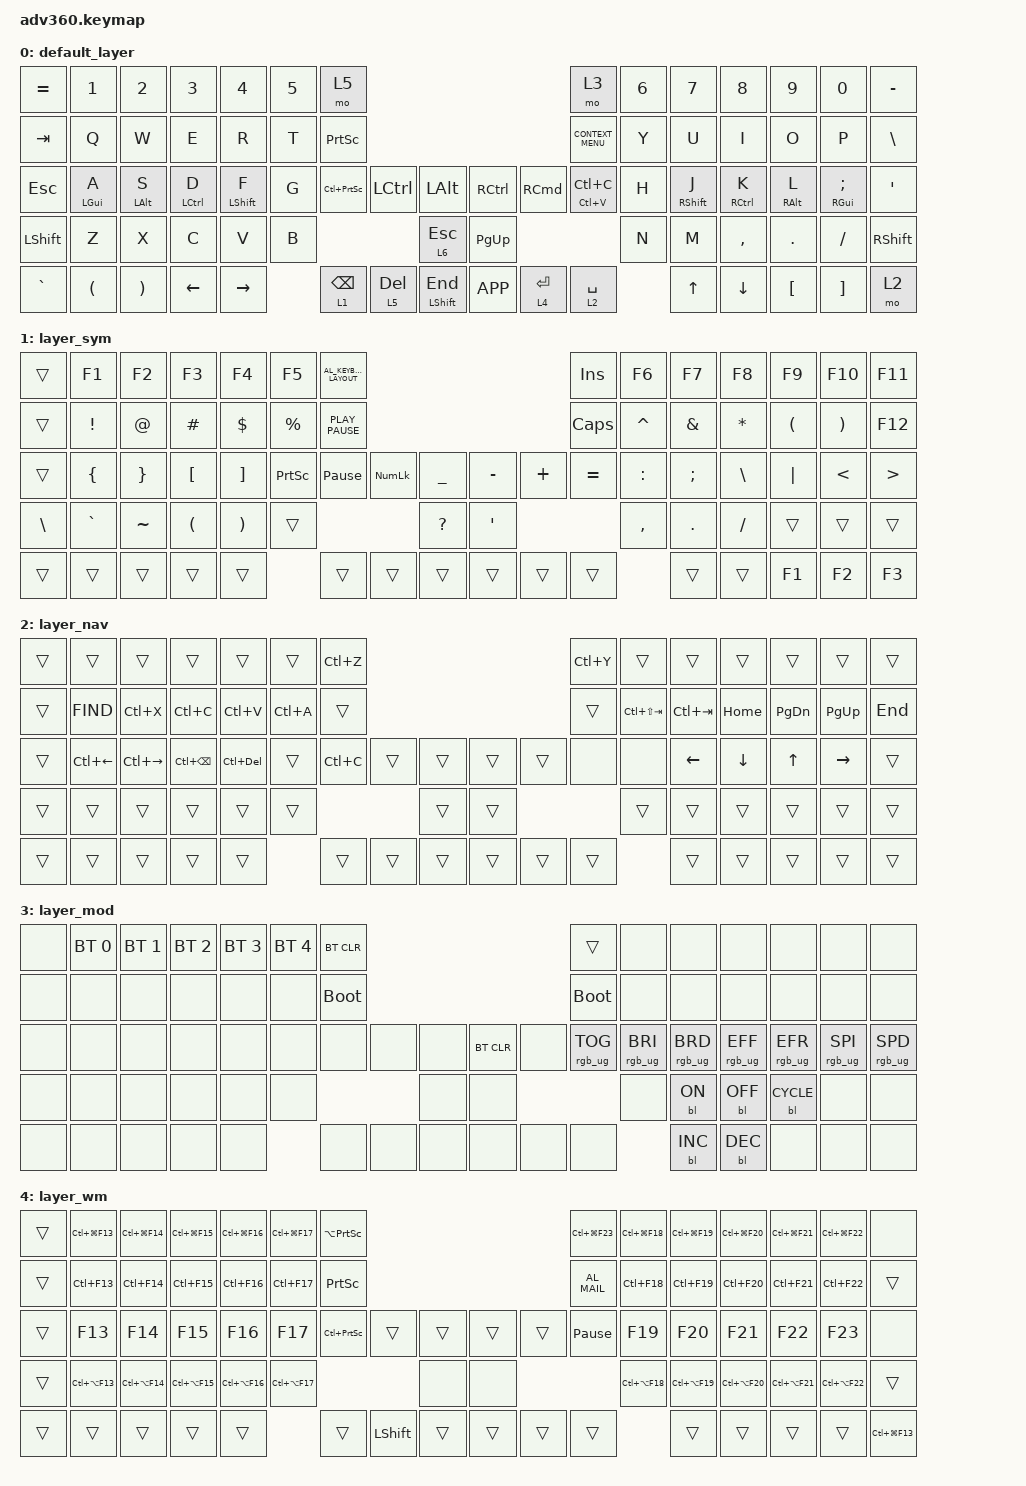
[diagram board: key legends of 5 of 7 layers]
/*
 * ZMK keymap for Kinesis Advantage360 Pro
 * Layers:
 * 0 BASE (QWERTY + HRM; thumb: tap End / hold Shift)
 * 1 SYM  (hold BSPC/DEL)
 * 2 NAV  (hold SPACE)
 * 3 MOD  (BT/RGB/boot)
 * 4 WM   (hold ENTER) -> focus with Enter+key; move requires Shift
 * 5 NUMPAD (momentary from base top row)
 * 6 APP  (hold CAPS position, tap ESC) -> Ctrl+Alt+Win+<key> for quicklaunch/system binds
 */

#include <behaviors.dtsi>
#include <dt-bindings/zmk/backlight.h>
#include <dt-bindings/zmk/bt.h>
#include <dt-bindings/zmk/keys.h>
#include <dt-bindings/zmk/rgb.h>

/ {
    behaviors {
        hm: home_row_mods {
            compatible = "zmk,behavior-hold-tap";
            label = "HOME_ROW_MODS";
            #binding-cells = <2>;
            tapping-term-ms = <200>;
            quick-tap-ms = <0>;
            require-prior-idle-ms = <150>;
            flavor = "tap-preferred";
            bindings = <&kp>, <&kp>;
        };
    };

    keymap {
        compatible = "zmk,keymap";

        // =========================================================
        // LAYER 0: BASE
        // =========================================================

        default_layer {
            bindings = <
&kp EQUAL  &kp N1                &kp N2                 &kp N3       &kp N4       &kp N5  &mo 5                                                                            &mo 3               &kp N6  &kp N7       &kp N8       &kp N9      &kp N0         &kp MINUS
&kp TAB    &kp Q                 &kp W                  &kp E        &kp R        &kp T   &kp PRINTSCREEN                                                                  &kp K_CONTEXT_MENU  &kp Y   &kp U        &kp I        &kp O       &kp P          &kp BSLH
&kp ESC    &hm LGUI A            &hm LALT S             &hm LCTRL D  &hm LSHFT F  &kp G   &kp LC(PRINTSCREEN)  &kp LCTRL  &kp LEFT_ALT       &kp RCTRL  &kp RIGHT_COMMAND  &mt LC(V) LC(C)     &kp H   &hm RSHFT J  &hm RCTRL K  &hm RALT L  &hm RGUI SEMI  &kp SQT
&kp LSHFT  &kp Z                 &kp X                  &kp C        &kp V        &kp B                                   &lt 6 ESC          &kp PG_UP                                         &kp N   &kp M        &kp COMMA    &kp DOT     &kp FSLH       &kp RSHFT
&kp GRAVE  &kp LEFT_PARENTHESIS  &kp RIGHT_PARENTHESIS  &kp LEFT     &kp RIGHT            &lt 1 BSPC           &lt 5 DEL  &mt LSHFT END      &kp K_APP  &lt 4 ENTER        &lt 2 SPACE                 &kp UP       &kp DOWN     &kp LBKT    &kp RBKT       &mo 2
            >;
        };

        // =========================================================
        // LAYER 1: SYM
        // =========================================================

        layer_sym {
            bindings = <
&trans    &kp F1     &kp F2     &kp F3                &kp F4                 &kp F5           &kp C_AL_KEYBOARD_LAYOUT                                                  &kp INS    &kp F6     &kp F7    &kp F8         &kp F9    &kp F10   &kp F11
&trans    &kp EXCL   &kp AT     &kp HASH              &kp DLLR               &kp PRCNT        &kp K_PLAY_PAUSE                                                          &kp CAPS   &kp CARET  &kp AMPS  &kp STAR       &kp LPAR  &kp RPAR  &kp F12
&trans    &kp LBRC   &kp RBRC   &kp LBKT              &kp RBKT               &kp PRINTSCREEN  &kp PAUSE_BREAK           &kp KP_NUM  &kp UNDER      &kp MINUS  &kp PLUS  &kp EQUAL  &kp COLON  &kp SEMI  &kp BACKSLASH  &kp PIPE  &kp LT    &kp GT
&kp BSLH  &kp GRAVE  &kp TILDE  &kp LEFT_PARENTHESIS  &kp RIGHT_PARENTHESIS  &trans                                                 &kp QMARK      &kp SQT                         &kp COMMA  &kp DOT   &kp FSLH       &trans    &trans    &trans
&trans    &trans     &trans     &trans                &trans                                  &trans                    &trans      &trans         &trans     &trans    &trans                &trans    &trans         &kp F1    &kp F2    &kp F3
            >;
        };

        // =========================================================
        // LAYER 2: NAV
        // =========================================================

        layer_nav {
            bindings = <
&trans  &trans        &trans         &trans        &trans       &trans  &kp LC(Z)                                      &kp LC(Y)  &trans       &trans    &trans          &trans        &trans     &trans
&trans  &kp K_FIND    &kp LC(X)      &kp LC(C)     &kp LC(V)    &kp LC(A)  &trans                                      &trans     &kp LC(LS(TAB))  &kp LC(TAB)  &kp HOME  &kp PAGE_DOWN  &kp PG_UP  &kp END
&trans  &kp LC(LEFT)  &kp LC(RIGHT)  &kp LC(BSPC)  &kp LC(DEL)  &trans  &kp LC(C)  &trans  &trans      &trans  &trans  &none      &none        &kp LEFT  &kp DOWN_ARROW  &kp UP_ARROW  &kp RIGHT  &trans
&trans  &trans        &trans         &trans        &trans       &trans                     &trans      &trans                     &trans       &trans    &trans          &trans        &trans     &trans
&trans  &trans        &trans         &trans        &trans               &trans     &trans  &trans      &trans  &trans  &trans                  &trans    &trans          &trans        &trans     &trans
            >;
        };

        // =========================================================
        // LAYER 3: MOD (BT/RGB/boot)
        // =========================================================

        layer_mod {
            bindings = <
&none  &bt BT_SEL 0  &bt BT_SEL 1  &bt BT_SEL 2  &bt BT_SEL 3  &bt BT_SEL 4  &bt BT_CLR                                        &trans           &none            &none            &none            &none            &none            &none
&none  &none         &none         &none         &none         &none         &bootloader                                       &bootloader      &none            &none            &none            &none            &none            &none
&none  &none         &none         &none         &none         &none         &none        &none  &none      &bt BT_CLR  &none  &rgb_ug RGB_TOG  &rgb_ug RGB_BRI  &rgb_ug RGB_BRD  &rgb_ug RGB_EFF  &rgb_ug RGB_EFR  &rgb_ug RGB_SPI  &rgb_ug RGB_SPD
&none  &none         &none         &none         &none         &none                             &none      &none                               &none            &bl BL_ON        &bl BL_OFF       &bl BL_CYCLE     &none            &none
&none  &none         &none         &none         &none                       &none        &none  &none      &none       &none  &none                             &bl BL_INC       &bl BL_DEC       &none            &none            &none
            >;
        };

        // =========================================================
        // LAYER 4: WM
        // =========================================================

        layer_wm {
            bindings = <
&trans  &kp LC(LG(F13))  &kp LC(LG(F14))  &kp LC(LG(F15))  &kp LC(LG(F16))  &kp LC(LG(F17))  &kp LA(PRINTSCREEN)                                              &kp LC(LG(F23))  &kp LC(LG(F18))  &kp LC(LG(F19))  &kp LC(LG(F20))  &kp LC(LG(F21))  &kp LC(LG(F22))  &none
&trans  &kp LC(F13)      &kp LC(F14)      &kp LC(F15)      &kp LC(F16)      &kp LC(F17)      &kp PRINTSCREEN                                                  &kp C_AL_MAIL    &kp LC(F18)      &kp LC(F19)      &kp LC(F20)      &kp LC(F21)      &kp LC(F22)      &trans
&trans  &kp F13          &kp F14          &kp F15          &kp F16          &kp F17          &kp LC(PSCRN)        &trans          &trans      &trans  &trans  &kp PAUSE_BREAK  &kp F19          &kp F20          &kp F21          &kp F22          &kp F23          &none
&trans  &kp LC(LA(F13))  &kp LC(LA(F14))  &kp LC(LA(F15))  &kp LC(LA(F16))  &kp LC(LA(F17))                                       &none       &none                            &kp LC(LA(F18))  &kp LC(LA(F19))  &kp LC(LA(F20))  &kp LC(LA(F21))  &kp LC(LA(F22))  &trans
&trans  &trans           &trans           &trans           &trans                            &trans               &kp LEFT_SHIFT  &trans      &trans  &trans  &trans                            &trans           &trans           &trans           &trans           &kp LC(LG(F13))
            >;
        };

        // =========================================================
        // LAYER 5: NUMPAD
        // =========================================================

        layer_numpad {
            bindings = <
&trans  &trans    &trans  &trans     &trans    &trans       &trans                                                                 &trans  &trans           &kp MINUS     &kp PLUS      &kp EQUAL     &kp PIPE       &trans
&trans  &trans    &trans  &trans     &trans    &trans       &kp KP_SLASH                                                           &trans  &trans           &kp N7        &kp N8        &kp N9        &kp BACKSLASH  &trans
&trans  &kp EXCL  &kp AT  &kp POUND  &kp DLLR  &kp PERCENT  &kp KP_MULTIPLY  &trans  &trans            &trans       &trans         &trans  &kp LOCKING_NUM  &kp NUMBER_4  &kp N5        &kp NUMBER_6  &kp DOT        &trans
&trans  &trans    &trans  &trans     &trans    &trans                                &kp KP_MINUS      &kp KP_PLUS                         &kp N0           &kp NUMBER_1  &kp NUMBER_2  &kp NUMBER_3  &kp SLASH      &trans
&trans  &trans    &trans  &trans     &trans                 &trans           &trans  &trans            &trans       &kp BACKSPACE  &trans                   &kp N0        &trans        &trans        &trans
            >;
        };

        // =========================================================
        // LAYER 6: APP (USE ALL KEYS)
        // Hold the CAPS-position key to access, tap it for ESC.
        // Sends Ctrl+Alt+Win+<key> for every position (except the held APP key).
        // Bind these in GlazeWM to launch apps / scripts.
        // =========================================================

        layer_app {
            bindings = <
&kp LC(LA(LG(EQUAL)))  &kp LC(LA(LG(N1)))     &kp LC(LA(LG(N2)))  &kp LC(LA(LG(N3)))    &kp LC(LA(LG(N4)))     &kp LC(LA(LG(N5)))  &kp LC(LA(LG(F1)))                                                                                                 &kp LC(LA(LG(F2)))     &kp LC(LA(LG(N6)))  &kp LC(LA(LG(N7)))  &kp LC(LA(LG(N8)))     &kp LC(LA(LG(N9)))    &kp LC(LA(LG(N0)))    &kp LC(LA(LG(MINUS)))
&kp LC(LA(LG(TAB)))    &kp LC(LA(LG(Q)))      &kp LC(LA(LG(W)))   &kp LC(LA(LG(E)))     &kp LC(LA(LG(R)))      &kp LC(LA(LG(T)))   &kp LC(LA(LG(F3)))                                                                                                 &kp LC(LA(LG(F4)))     &kp LC(LA(LG(Y)))   &kp LC(LA(LG(U)))   &kp LC(LA(LG(I)))      &kp LC(LA(LG(O)))     &kp LC(LA(LG(P)))     &kp LC(LA(LG(BSLH)))
&kp LC(LA(LG(ESC)))    &kp LC(LA(LG(A)))      &kp LC(LA(LG(S)))   &kp LC(LA(LG(D)))     &kp LC(LA(LG(F)))      &kp LC(LA(LG(G)))   &kp LC(LA(LG(F5)))    &kp LC(LA(LG(F6)))   &kp LC(LA(LG(F7)))        &kp LC(LA(LG(F8)))     &kp LC(LA(LG(F9)))     &kp LC(LA(LG(F10)))    &kp LC(LA(LG(H)))   &kp LC(LA(LG(J)))   &kp LC(LA(LG(K)))      &kp LC(LA(LG(L)))     &kp LC(LA(LG(SEMI)))  &kp LC(LA(LG(SQT)))
&kp LC(LA(LG(LSHFT)))  &kp LC(LA(LG(Z)))      &kp LC(LA(LG(X)))   &kp LC(LA(LG(C)))     &kp LC(LA(LG(V)))      &kp LC(LA(LG(B)))                                              &kp LC(LA(LG(HOME)))      &kp LC(LA(LG(PG_UP)))                                                &kp LC(LA(LG(N)))   &kp LC(LA(LG(M)))   &kp LC(LA(LG(COMMA)))  &kp LC(LA(LG(DOT)))   &kp LC(LA(LG(FSLH)))  &kp LC(LA(LG(RSHFT)))
&kp LC(LA(LG(GRAVE)))  &kp LC(LA(LG(GRAVE)))  &trans              &kp LC(LA(LG(LEFT)))  &kp LC(LA(LG(RIGHT)))                      &kp LC(LA(LG(BSPC)))  &kp LC(LA(LG(DEL)))  &kp LC(LA(LG(END)))       &kp LC(LA(LG(PG_DN)))  &kp LC(LA(LG(ENTER)))  &kp LC(LA(LG(SPACE)))                      &kp LC(LA(LG(UP)))  &kp LC(LA(LG(DOWN)))   &kp LC(LA(LG(LBKT)))  &kp LC(LA(LG(RBKT)))  &kp LC(LA(LG(F11)))
            >;
        };
    };
};
